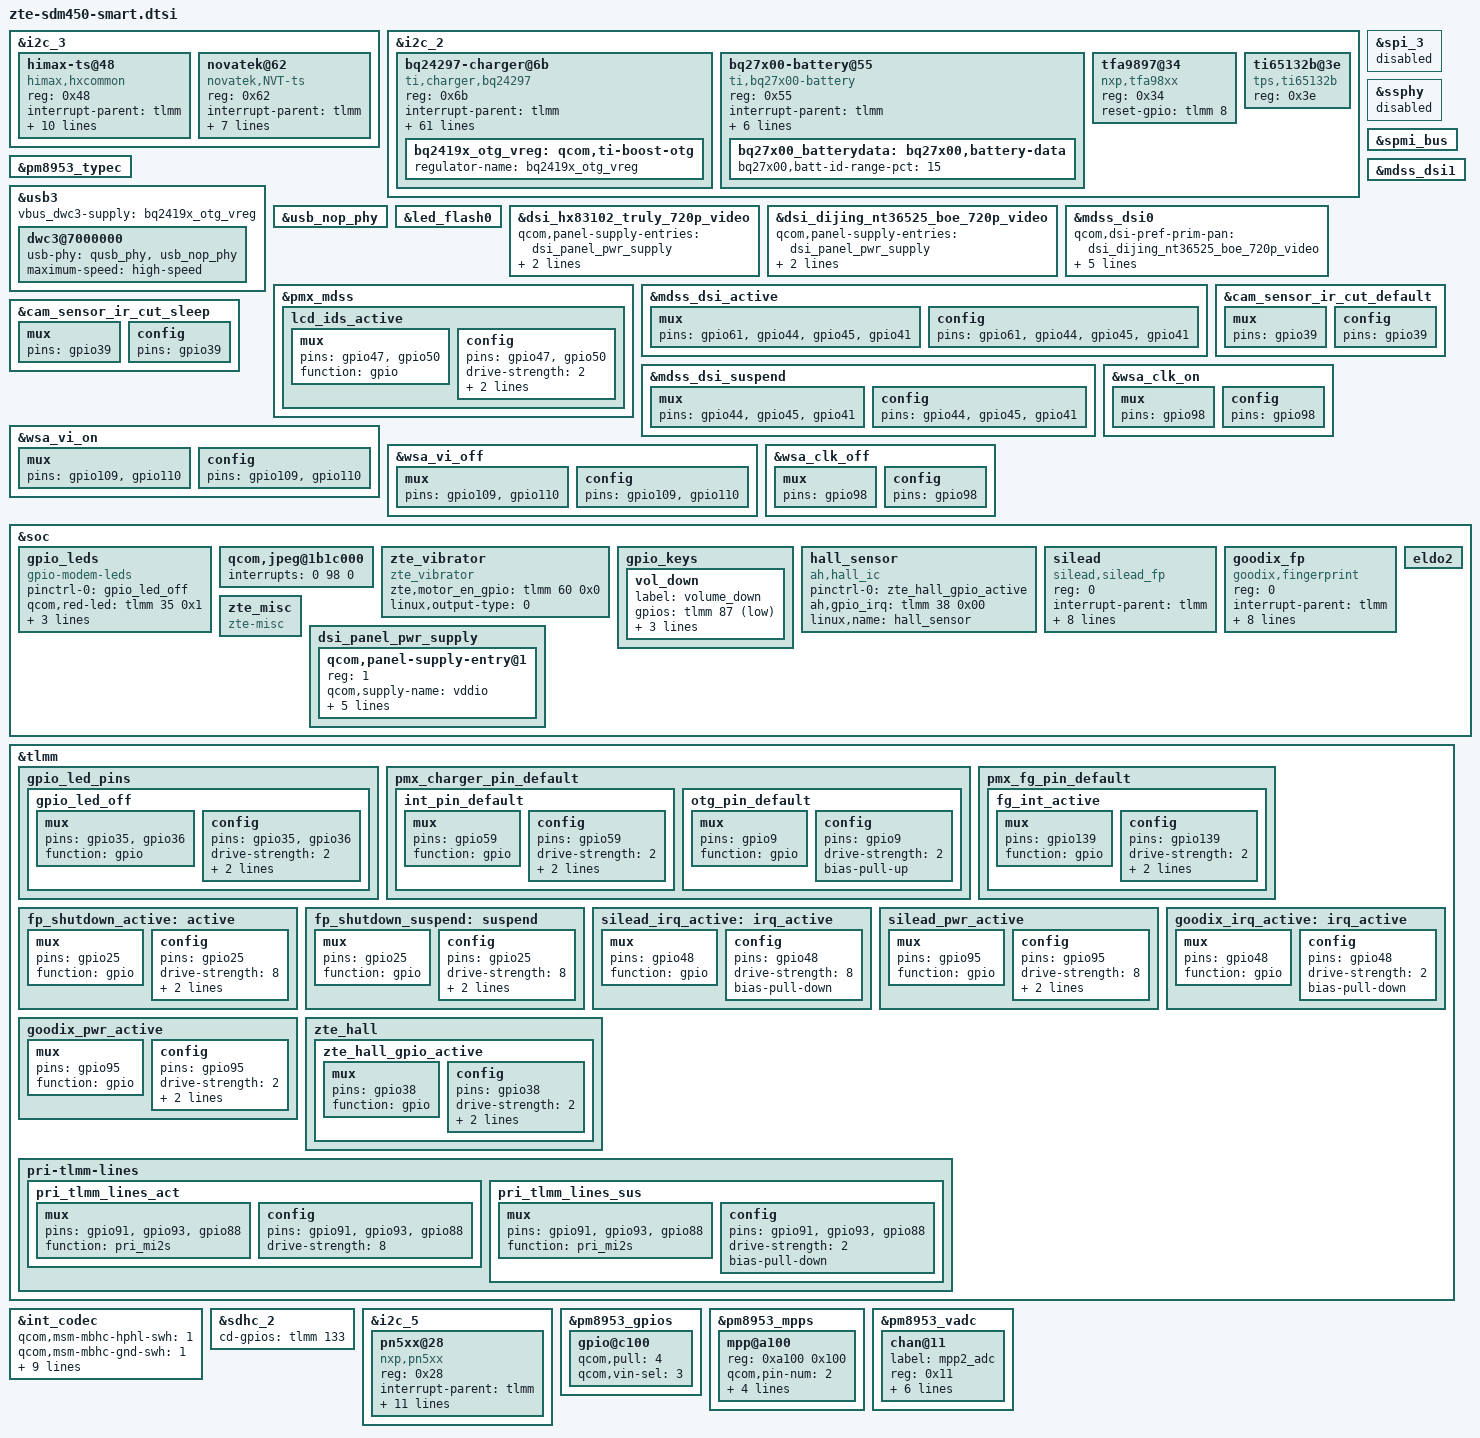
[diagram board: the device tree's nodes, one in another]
/*
 * Copyright (c) 2017, The Linux Foundation. All rights reserved.
 *
 * This program is free software; you can redistribute it and/or modify
 * it under the terms of the GNU General Public License version 2 and
 * only version 2 as published by the Free Software Foundation.
 *
 * This program is distributed in the hope that it will be useful,
 * but WITHOUT ANY WARRANTY; without even the implied warranty of
 * MERCHANTABILITY or FITNESS FOR A PARTICULAR PURPOSE.  See the
 * GNU General Public License for more details.
 */

#include "sdm450-camera-sensor-zte-smart.dtsi"

#include "dsi-panel-truly-hx83102-cpt-5p7-720p-video.dtsi"
#include "dsi-panel-dijing-nt36525-boe-5p7-720p-video-a7.dtsi"

&i2c_3 { /* BLSP1 QUP3 */
	status = "okay";

	himax-ts@48 {
		compatible = "himax,hxcommon";
		reg = <0x48>;
		interrupt-parent = <&tlmm>;
		interrupts = <65 0x2>;
		vdd-supply = <&pm8953_l17>;
		avdd-supply = <&pm8953_l6>;
		himax,panel-coords = <0 720 0 1440>;
		himax,display-coords = <0 720 0 1440>;
		himax,irq-gpio = <&tlmm 65 0x00>;
		himax,rst-gpio = <&tlmm 64 0x00>;
		himax,id0-gpio = <&tlmm 47 0x00>;
		himax,id1-gpio = <&tlmm 50 0x00>;
		report_type = <1>;
	};

	novatek@62 {
		compatible = "novatek,NVT-ts";
		reg = <0x62>;
		interrupt-parent = <&tlmm>;
		interrupts = <65 0x2>;
		vdd-supply = <&pm8953_l17>;
		avdd-supply = <&pm8953_l6>;
		pinctrl-names = "pmx_ts_active", "pmx_ts_suspend";
		pinctrl-0 = <&ts_int_active &ts_reset_active>;
		pinctrl-1 = <&ts_int_suspend &ts_reset_suspend>;
		novatek,reset-gpio = <&tlmm 64 0x00>;
		novatek,irq-gpio = <&tlmm 65 0x2008>;
	};
};

&i2c_2 {
	bq24297-charger@6b {
		compatible = "ti,charger,bq24297";
		reg = <0x6b>;
		interrupt-parent = <&tlmm>;
		interrupts = <59 0x0>;

		pinctrl-names = "default";
		pinctrl-0 = <&int_pin_default &otg_pin_default>;

		ti,irq-gpio = <&tlmm 9 0x00>;

		ti,bq2429x,usb-vlim = <4520>;
		ti,bq2429x,usb-ilim = <500>;
		ti,bq2429x,usb-float-voltage-mv = <4400>;
		ti,bq2429x,usb-ichg = <512>;
		ti,bq2429x,ta-vlim = <4520>;
		ti,bq2429x,ta-ilim = <2000>;
		ti,bq2429x,ta-ichg = <2240>;
		ti,bq2429x,ta-float-voltage-mv = <4400>;
		ti,recharge-mv = <100>;
		ti,bq2429x,software-jeita-supported;
		ti,bq2429x,jeita-hot-degc = <600>;
		ti,bq2429x,jeita-warm-degc = <450>;
		ti,bq2429x,jeita-cool-degc = <100>;
		ti,bq2429x,jeita-cold-degc = <50>;
		ti,bq2429x,jeita-cool-ma = <1024>;
		ti,bq2429x,jeita-cool-mv = <4400>;
		ti,bq2429x,jeita-warm-ma = <1024>;
		ti,bq2429x,jeita-warm-mv = <4100>;
		ti,bq2429x,jeita-cold-hysteresis = <20>;
		ti,bq2429x,jeita-hot-hysteresis = <20>;
		ti,bq2429x,thermal-mitigation = <2000 1500 1000 700>;
		ti,bq2429x,precharge-current = <384>;
		ti,bq2429x,termination-current = <128>;
		ti,bq2429x,boost-volt = <4998>;
		ti,bq2429x,boost-current = <1000>;
		ti,bq2429x,enable_term;

		/*--------------------------fot ti bq25601 compatible---------------------------------------*/
		ti,charge_enable-gpio = <&tlmm 3 0x00>;

		ti,bq2560x,usb-vlim = <4520>;
		ti,bq2560x,usb-ilim = <500>;
		ti,bq2560x,usb-vreg = <4400>;
		ti,bq2560x,usb-ichg = <500>;

		ti,bq2560x,ta-vlim = <4520>;
		ti,bq2560x,ta-ilim = <2000>;
		ti,bq2560x,ta-vreg = <4400>;
		ti,bq2560x,ta-ichg = <2000>;

		ti,bq2560x,precharge-current = <384>;
		ti,bq2560x,termination-current = <60>;
		ti,bq2560x,boost-voltage = <4998>;
		ti,bq2560x,boost-current = <1200>;

		ti,bq2560x,stat-pin-ctrl = <0>;
		ti,bq2560x,vac-ovp-threshold = <14300>;

		ti,bq2560x,jeita-hot-degc = <600>;
		ti,bq2560x,jeita-warm-degc = <450>;
		ti,bq2560x,jeita-cool-degc = <100>;
		ti,bq2560x,jeita-cold-degc = <0>;

		ti,bq2560x,jeita-hot-hysteresis = <50>;
		ti,bq2560x,jeita-cold-hysteresis = <50>;

		ti,bq2560x,jeita-cool-ma = <600>;
		ti,bq2560x,jeita-cool-mv = <4352>;
		ti,bq2560x,jeita-warm-ma = <600>;
		ti,bq2560x,jeita-warm-mv = <4100>;

		ti,bq2560x,recharge-mv = <300>;

		ti,bq2560x,enable_term;
		ti,bq2560x,enable_soc_term_charge;
		ti,bq2560x,software-jeita-supported;
		ti,bq2560x,thermal-mitigation = <1500 700 500 500>;

		bq2419x_otg_vreg: qcom,ti-boost-otg {
			regulator-name = "bq2419x_otg_vreg";
		};
	};

	bq27x00-battery@55 {
		compatible = "ti,bq27x00-battery";
		reg = <0x55>;
		interrupt-parent = <&tlmm>;
		interrupts = <139 0x0>;
		qcom,irq-gpio = <&tlmm 139 0x00>;

		pinctrl-names = "default";
		pinctrl-0 = <&fg_int_active>;

		qcom,chg-vadc = <&pm8953_vadc>;
		qcom,batt-id-vref-uv = <1800000>;
		qcom,batt-id-rpullup-kohm = <100>;

		bq27x00_batterydata: bq27x00,battery-data {
			bq27x00,batt-id-range-pct = <15>;
			#include "batterydata-ti-450-18-10k-4000mah-jiade.dtsi"
			#include "batterydata-ti-450-18-20k-4000mah-guangyu.dtsi"
			#include "batterydata-ti-450-18-390k-4000mah-tianmao.dtsi"
		};
	};

	/*zte weiguohua add it for nxp smart pa chip*/
	tfa9897@34 {
		compatible = "nxp,tfa98xx";
		reg = <0x34>;
		reset-gpio = <&tlmm 8 0x0>;
	};
	/*zte weiguohua add it for nxp smart pa chip*/

	/*zte yujianhua add for lcd bl voltage start*/
	ti65132b@3e {
		compatible = "tps,ti65132b";
		reg = <0x3e>;
	};
	/*zte yujianhua add for lcd bl voltage end*/
};

&spi_3 {
	status = "disabled";
};

&pm8953_typec {
	/delete-property/qcom,ssmux-gpio;
	/delete-property/pinctrl-names;
	/delete-property/pinctrl-0;
	/*qcom,role-reversal-supported;*/
};

&usb3 {
	vbus_dwc3-supply = <&bq2419x_otg_vreg>;
	dwc3@7000000 {
		usb-phy = <&qusb_phy>, <&usb_nop_phy>;
		maximum-speed = "high-speed";
	};
};

&usb_nop_phy {
	status = "okay";
};

&ssphy {
	status = "disabled";
};

&spmi_bus {
	/delete-node/qcom,pmi8950@2;
	/delete-node/qcom,pmi8950@3;
};

&led_flash0 {
	/delete-property/qcom,flash-source;
	/delete-property/qcom,torch-source;
	/delete-property/qcom,switch-source;
};

&dsi_hx83102_truly_720p_video{
	qcom,panel-supply-entries = <&dsi_panel_pwr_supply>;
	qcom,mdss-dsi-panel-timings-phy-v2 = [24 1F 08 09 05 03 04 a0
		24 1F 08 09 05 03 04 a0
		24 1F 08 09 05 03 04 a0
		24 1F 08 09 05 03 04 a0
		24 1B 08 09 05 03 04 a0];
};
&dsi_dijing_nt36525_boe_720p_video{
	qcom,panel-supply-entries = <&dsi_panel_pwr_supply>;
	qcom,mdss-dsi-panel-timings-phy-v2 = [24 1F 08 09 05 03 04 a0
		24 1F 08 09 05 03 04 a0
		24 1F 08 09 05 03 04 a0
		24 1F 08 09 05 03 04 a0
		24 1B 08 09 05 03 04 a0];
};
&mdss_dsi0 {
	qcom,dsi-pref-prim-pan = <&dsi_hx83102_truly_720p_video>;
	qcom,dsi-pref-prim-pan = <&dsi_dijing_nt36525_boe_720p_video>;
	pinctrl-0 = <&mdss_dsi_active &mdss_te_active &lcd_ids_active>;
	qcom,platform-bklight-en-gpio = <&tlmm 41 0>;
	zte,disp_vsp_en_gpio = <&tlmm 44 0>;
	zte,disp_vsn_en_gpio = <&tlmm 45 0>;
	/delete-property/lab-supply;
	/delete-property/ibb-supply;
};

&mdss_dsi1 {
	/delete-property/lab-supply;
	/delete-property/ibb-supply;
};

&dsi_hx83102_truly_720p_video{
	qcom,panel-supply-entries = <&dsi_panel_pwr_supply>;
};
&dsi_dijing_nt36525_boe_720p_video{
	qcom,panel-supply-entries = <&dsi_panel_pwr_supply>;
};

&pmx_mdss {
	lcd_ids_active: lcd_ids_active {
		mux {
			pins = "gpio47","gpio50";
			function = "gpio";
		};
		config {
			pins =  "gpio47","gpio50";
			drive-strength = <2>;
			bias-pull-down;
			input-enable;
		};
	};
};
&mdss_dsi_active {
	mux {
		pins = "gpio61", "gpio44","gpio45", "gpio41";
	};

	config {
		pins = "gpio61", "gpio44","gpio45", "gpio41";
	};
};

&mdss_dsi_suspend {
	mux {
		pins = "gpio44","gpio45", "gpio41";
	};

	config {
		pins = "gpio44","gpio45", "gpio41";
	};
};

/*added by zte_sw_chenhui for hall*/
&cam_sensor_ir_cut_default {
	/* RESET, STANDBY */
	mux {
		pins = "gpio39";
	};

	config {
		pins = "gpio39";
	};
};

&cam_sensor_ir_cut_sleep {
	/* RESET, STANDBY */
	mux {
		pins = "gpio39";
	};

	config {
		pins = "gpio39";
	};
};
/*end*/
/*add zte_sw_chenhui fingerprint, begin*/
&wsa_vi_on {
	mux {
		pins = "gpio109", "gpio110";
	};

	config {
		pins = "gpio109", "gpio110";
	};
};

&wsa_vi_off {
	mux {
		pins = "gpio109", "gpio110";
	};

	config {
		pins = "gpio109", "gpio110";
	};
};
&wsa_clk_on {
	mux {
		pins = "gpio98";
	};

	config {
		pins = "gpio98";
	};
};

&wsa_clk_off {
	mux {
		pins = "gpio98";
	};

	config {
		pins = "gpio98";
	};
};
/*end*/

&soc {
	/* added by zte_fangjun for color_led,start */
	gpio_leds {
		compatible = "gpio-modem-leds";
		status = "okay";
		pinctrl-names = "default";
		pinctrl-0 = <&gpio_led_off>;
		qcom,red-led = <&tlmm 35 0x1>;
		qcom,green-led = <&tlmm 36 0x1>;
		/*qcom,trickle_red-led = <&tlmm 3 0x1>;*/
		qcom,blink-on-time = <500>;
		qcom,blink-off-time = <1500>;
	};

	/* added by zte_sw_fangjun for color_led,end */
	qcom,jpeg@1b1c000 {
		interrupts = <0 98 0>;
	};

	zte_vibrator {
		compatible = "zte_vibrator";
		zte,motor_en_gpio = <&tlmm 60 0x0>;
		linux,output-type = <0>;
	};

	gpio_keys {
		/delete-node/camera_focus;
		vol_down {
			label = "volume_down";
			gpios = <&tlmm 87 0x1>;
			linux,input-type = <1>;
			linux,code = <114>;
			debounce-interval = <15>;
		};
	};

/*added by zte_sw_chenhui for hall*/
	hall_sensor {
		compatible = "ah,hall_ic";
		pinctrl-names = "zte_hall_gpio_active";
		pinctrl-0 = <&zte_hall_gpio_active>;
		ah,gpio_irq = <&tlmm 38 0x00>;
		linux,name = "hall_sensor";
	};
/*end*/
/*Added by shizuyong for fingerprint, begin*/
	silead {
		status = "ok";
		reg = <0>;
		compatible = "silead,silead_fp";
		interrupt-parent = <&tlmm>;
		interrupts = <48 0x0>;

		pinctrl-names = "silead_active", "silead_suspend", "silead_irq", "pwr_active";
		pinctrl-0 = <&fp_shutdown_active>;
		pinctrl-1 = <&fp_shutdown_suspend>;
		pinctrl-2 = <&silead_irq_active>;
		pinctrl-3 = <&silead_pwr_active>;

		silead,gpio_reset = <&tlmm 25 0>;
		silead,gpio_irq = <&tlmm 48 0>;
		silead,gpio_pwr = <&tlmm 95 0>;
		interrupt-names = "sl_wake_up";
	};
	goodix_fp {
		status = "ok";
		reg = <0>;
		compatible = "goodix,fingerprint";
		interrupt-parent = <&tlmm>;
		interrupts = <48 0x0>;

		pinctrl-names = "goodix_active", "goodix_suspend", "goodix_irq", "pwr_active";
		pinctrl-0 = <&fp_shutdown_active>;
		pinctrl-1 = <&fp_shutdown_suspend>;
		pinctrl-2 = <&goodix_irq_active>;
		pinctrl-3 = <&goodix_pwr_active>;

		fp-gpio-reset = <&tlmm 25 0>;
		fp-gpio-irq = <&tlmm 48 0>;
		goodix,gpio_pwr = <&tlmm 95 0>;
		interrupt-names = "goodix_wake_up";
	};
	zte_misc {
		compatible = "zte-misc";
	};
/*Added by shizuyong for silead, end*/

	dsi_panel_pwr_supply: dsi_panel_pwr_supply {
		qcom,panel-supply-entry@1 {
			reg = <1>;
			qcom,supply-name = "vddio";
			qcom,supply-min-voltage = <1800000>;
			qcom,supply-max-voltage = <1800000>;
			qcom,supply-enable-load = <100000>;
			qcom,supply-disable-load = <100>;
			qcom,supply-post-on-sleep = <1>;
		};
	};
	eldo2 {
		/delete-property/compatible;
		/delete-property/regulator-name;
		/delete-property/startup-delay-us;
		/delete-property/enable-active-high;
		/delete-property/gpio;
		/delete-property/regulator-always-on;
	};
};

&tlmm {
	gpio_led_pins {
		gpio_led_off: gpio_led_off {
			mux {
				pins = "gpio35", "gpio36";
				function = "gpio";
			};

			config {
				pins = "gpio35", "gpio36";
				drive-strength = <2>;
				bias-disable;
				output-low;
			};
		};
	};
	pmx_charger_pin_default {
		int_pin_default: int_pin_default {
			mux {
				pins = "gpio59";
				function = "gpio";
			};

			config {
				pins = "gpio59";
				drive-strength = <2>;
				bias-pull-up;
				input-enable;
			};
		};
		otg_pin_default: otg_pin_default {
			mux {
				pins = "gpio9";
				function = "gpio";
			};

			config {
				pins = "gpio9";
				drive-strength = <2>;
				bias-pull-up;
			};
		};
	};

	/*added for fuelgague chip interrupt config begin*/
	pmx_fg_pin_default {
		fg_int_active: fg_int_active {
			mux {
				pins = "gpio139";
				function = "gpio";
			};

			config {
				pins = "gpio139";
				drive-strength = <2>;
				bias-pull-up;
				input-enable;
			};
		};
	};
	/*added for fuelgague chip interrupt config end*/

/*added by shizuyong for fingerprint,begin*/
    fp_shutdown_active:active{
	    mux{
		pins = "gpio25";
		function = "gpio";
	    };
	    config{
		pins = "gpio25";
		drive-strength = <8>;
		bias-disable;
		output-high;
	    };
	};
	fp_shutdown_suspend:suspend{
	    mux{
		pins = "gpio25";
		function = "gpio";
	    };
	    config{
		pins = "gpio25";
		drive-strength = <8>;
		bias-disable;
		output-low;
	    };
	};
    silead_irq_active:irq_active{
	    mux{
		pins = "gpio48";
		function = "gpio";
	    };
	    config{
		pins = "gpio48";
		drive-strength = <8>;
		bias-pull-down;
	    };
	};
    silead_pwr_active: silead_pwr_active {
	    mux{
		pins = "gpio95";
		function = "gpio";
	    };
	    config {
		pins = "gpio95";
		drive-strength = <8>;
		bias-disable;
		output-high;
	};
	};
	goodix_irq_active:irq_active{
			mux{
				pins = "gpio48";
				function = "gpio";
			};
			config{
				pins = "gpio48";
				drive-strength = <2>;
				bias-pull-down;
			};
	};
	goodix_pwr_active: goodix_pwr_active {
			mux{
				pins = "gpio95";
				function = "gpio";
			};
			config {
				pins = "gpio95";
				drive-strength = <2>;
				bias-disable;
				output-high;
		};
	};
/*end*/
/*added by chenhui for hall gpio for no pull*/
	zte_hall: zte_hall {
		zte_hall_gpio_active: zte_hall_gpio_active {
			mux {
				pins = "gpio38";
				function = "gpio";
			};
			config {
				pins = "gpio38";
				drive-strength = <2>; /* 2 mA */
				bias-pull-up;
				input-enable; /* input */
			};
		};
	};
/*end*/
	pri-tlmm-lines {
			pri_tlmm_lines_act: pri_tlmm_lines_act {
				mux {
					pins = "gpio91", "gpio93", "gpio88";
					function = "pri_mi2s";
				};

				config {
					pins = "gpio91", "gpio93", "gpio88";
					drive-strength = <8>;
				};
			};

			pri_tlmm_lines_sus: pri_tlmm_lines_sus {
				mux {
					pins = "gpio91", "gpio93", "gpio88";
					function = "pri_mi2s";
				};

				config {
					pins = "gpio91", "gpio93", "gpio88";
					drive-strength = <2>;
					bias-pull-down;
				};
			};
		};
};

&int_codec {
	qcom,msm-mbhc-hphl-swh = <1>;
	qcom,msm-mbhc-gnd-swh = <1>;
	qcom,msm-hs-micbias-type = "internal";
	zte,speaker-mode-switch-gpios = <&tlmm 8 0x0>;
	qcom,audio-routing =
		"RX_BIAS", "MCLK",
		"SPK_RX_BIAS", "MCLK",
		"INT_LDO_H", "MCLK",
		"MIC BIAS External", "Handset Mic",
		"MIC BIAS Internal2", "Headset Mic",
		"MIC BIAS External", "Secondary Mic",
		"AMIC1", "MIC BIAS External",
		"AMIC2", "MIC BIAS Internal2",
		"AMIC3", "MIC BIAS External";
		/* WSA_SPK OUT", "VDD_WSA_SWITCH", */
		/* "SpkrMono WSA_IN", "WSA_SPK OUT"; */

	/delete-property/ asoc-wsa-codec-names;
	/delete-property/ asoc-wsa-codec-prefixes;

	/delete-property/ msm-vdd-wsa-switch-supply;
	/delete-property/ qcom,msm-vdd-wsa-switch-voltage;
	/delete-property/ qcom,msm-vdd-wsa-switch-current;
	/delete-property/ qcom,hdmi-dba-codec-rx;
	/delete-property/ qcom,cdc-us-euro-gpios;
};

/*zteadd by yangshentao10176221 for F10 SD cd pin start*/
&sdhc_2 {
	cd-gpios = <&tlmm 133 0x0>;
};
/*zteadd by yangshentao10176221 for F10 SD cd pin end*/

&i2c_5 {
	/delete-node/nq@28;
};

&i2c_5 {
	pn5xx@28{
		compatible = "nxp,pn5xx";
		reg = <0x28>;
		interrupt-parent = <&tlmm>;
		interrupts = <17 0>;
		nxp,pn5xx-irq = <&tlmm 17 0x00>;
		nxp,pn5xx-ven = <&tlmm 16 0x00>;
		nxp,pn5xx-fw-dwnld = <&tlmm 62 0x00>;
		nxp,pn5xx-ese-pwr = <&tlmm 141 0x00>;
		//nxp,pn5xx-swp2-pwr = <&tlmm129 0x00>;
		//nxp,int_active_low = <0>;
		nxp,pn5xx-clkreq = <&pm8953_gpios 2 0x00>;
		nxp,clk-src = "BBCLK2";
		interrupt-names = "nfc_irq";
		pinctrl-names = "nfc_active","nfc_suspend";
		pinctrl-0 = <&nfc_int_active &nfc_disable_active>;
		pinctrl-1 = <&nfc_int_suspend &nfc_disable_suspend>;
		clocks = <&clock_gcc clk_bb_clk2_pin>;
		clock-names = "bb_clk2";
	};
};
&pm8953_gpios {
	/* GPIO 2 (NFC_CLK_REQ) */
	gpio@c100 {
		qcom,pull = <4>;
		qcom,vin-sel = <3>;
	};

	/* GPIO 8 (typeC is not supported) */
	/*gpio@c700 {
		qcom,mode = <0>;
		qcom,pull = <4>;
		qcom,vin-sel = <2>;
		qcom,src-sel = <0>;
		status = "okay";
	};*/
};

&pm8953_mpps {
	mpp@a100 {
		/* MPP2 - BATT_ID config */
		reg = <0xa100 0x100>;
		qcom,pin-num = <2>;
		qcom,mode = <4>;
		qcom,src-sel = <0>;
		qcom,ain-route = <1>;
		qcom,master-en = <1>;
		/delete-property/qcom,invert;
	};
};

&pm8953_vadc {
	chan@11 {
		label = "mpp2_adc";
		reg = <0x11>;
		qcom,decimation = <0>;
		qcom,pre-div-channel-scaling = <0>;
		qcom,calibration-type = "absolute";
		qcom,scale-function = <0>;
		qcom,hw-settle-time = <1>;
		qcom,fast-avg-setup = <2>;
		/delete-property/qcom,vadc-thermal-node;
	};
};

